# haltium_isimcore register map
Vendor: Nordic Semiconductor; Series: nRFHaltium; File version: 1
CPU: CM33 r0p4, little endian, MPU, FPU, 3 interrupt priority bits, 480 interrupts
Registers are 32-bit, read-write, reset 0x0 unless marked. A register's access mark holds for its fields unless they carry their own. Offsets are from the block's base; [hi:lo] are bit positions; {n}, {i} and the like mark numbered series.

## GLOBAL_TSGEN_NS — GENERIC
Base 0xBF041000
Same registers: GENERIC6_NS 0x47021000, GENERIC7_NS 0x47022000, GENERIC8_NS 0x47023000, GENERIC9_NS 0x47024000, GENERIC6_S 0x57021000, GENERIC7_S 0x57022000, GENERIC8_S 0x57023000, GENERIC9_S 0x57024000, GLOBAL_ETB_NS 0xBF044000, GLOBAL_ETR_NS 0xBF045000
0x00 TASKS_GENERICTASK wo — Generic event
  [0] TASKS_GENERICTASK
    1=Trigger task
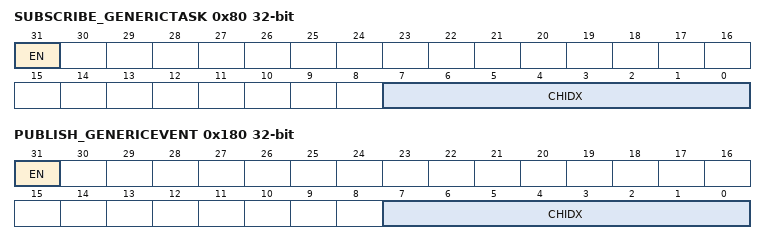
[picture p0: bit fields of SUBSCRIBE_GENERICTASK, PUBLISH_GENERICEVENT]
0x80 SUBSCRIBE_GENERICTASK — Subscribe configuration for task GENERICTASK
  [31] EN
    0=Disabled (Disable subscription); 1=Enabled (Enable subscription)
  [7:0] CHIDX — DPPI channel that task GENERICTASK will subscribe to
0x100 EVENTS_GENERICEVENT — Generic event
  [0] EVENTS_GENERICEVENT
    0=NotGenerated (Event not generated); 1=Generated (Event generated)
0x180 PUBLISH_GENERICEVENT — Publish configuration for event GENERICEVENT
  [31] EN
    0=Disabled (Disable publishing); 1=Enabled (Enable publishing)
  [7:0] CHIDX — DPPI channel that event GENERICEVENT will publish to
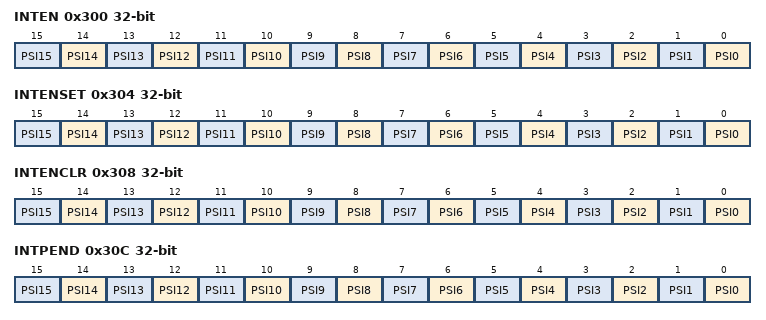
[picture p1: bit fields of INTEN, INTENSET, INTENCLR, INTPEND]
0x300 INTEN — Enable or disable interrupt
  [0] GENERICEVENT — Enable or disable interrupt for event GENERICEVENT
    0=Disabled; 1=Enabled
0x304 INTENSET — Enable interrupt
  [0] GENERICEVENT — Write '1' to enable interrupt for event GENERICEVENT
    on read: 0=Disabled (Read: Disabled); 1=Enabled (Read: Enabled) | on write: 1=Set (Enable)
0x308 INTENCLR — Disable interrupt
  [0] GENERICEVENT — Write '1' to disable interrupt for event GENERICEVENT
    on read: 0=Disabled (Read: Disabled); 1=Enabled (Read: Enabled) | on write: 1=Clear (Disable)

## CPUCONF_NS — CPU Configuration 0
Base 0x47001000
Same registers: CPUCONF_S 0x57001000
0x00 TASKS_ERASECACHE wo — Erase the caches used by the CPU.
  [0] TASKS_ERASECACHE
    1=Trigger task
0x500 INITSVTOR — Initial value of the secure VTOR (Vector Table Offset Register) after CPU reset.
  [31:0] INITSVTOR — Initial value of the VTOR.
0x504 INITNSVTOR — Initial value of the non-secure VTOR (Vector Table Offset Register).
  [31:0] INITNSVTOR — Initial value of the VTOR.
0x508 CPUSTART — Enable for starting the CPU
  [0] EN — Enable to start the CPU.
    0=Stopped (CPU stopped.); 1=Started (CPU started.)
0x50C CPUWAIT — Enable for the CPU wait.
  [0] EN — Enable to the CPU wait.
    0=Disabled (CPU is not waiting.); 1=Enabled (CPU is waiting.)

## CICTRL_NS — CI control 0
Base 0x47002000
Same registers: CICTRL_S 0x57002000
{0x100+4i} EVENTS_PSI[{i}] (i=0..15) — Description collection: Event generated from CryptoIsland Persistent State Interface PSI[n]
  [0] EVENTS_PSI — Event generated from CryptoIsland Persistent State Interface PSI[n]
    0=NotGenerated (Event not generated); 1=Generated (Event generated)
0x300 INTEN — Enable or disable interrupt
  [all] fields
    0=Disabled; 1=Enabled
  [n] PSI{n} (n=0..15) — Enable or disable interrupt for event PSI[{n}]
0x304 INTENSET — Enable interrupt
  [all] fields
    on read: 0=Disabled (Read: Disabled); 1=Enabled (Read: Enabled) | on write: 1=Set (Enable)
  [n] PSI{n} (n=0..15) — Write '1' to enable interrupt for event PSI[{n}]
0x308 INTENCLR — Disable interrupt
  [all] fields
    on read: 0=Disabled (Read: Disabled); 1=Enabled (Read: Enabled) | on write: 1=Clear (Disable)
  [n] PSI{n} (n=0..15) — Write '1' to disable interrupt for event PSI[{n}]
0x30C INTPEND ro — Pending interrupts
  [all] fields
    on read: 0=NotPending (Read: Not pending); 1=Pending (Read: Pending)
  [n] PSI{n} (n=0..15) — Read pending status of interrupt for event PSI[{n}]
0x400 PSI ro — CryptoIsland PSI status shadow register
  [15:0] PSI
0x404 POWERMODE reset 0x3 — CryptoIsland power mode control
  [1:0] POWERMODE
    0=SHUTDOWN (CryptoIsland to be put to shutdown mode); 1=HIBERNATE (CryptoIsland to be put to hibernate mode); 2=RETENTION (Reserved for future use); 3=RUN (Reserved for future use)
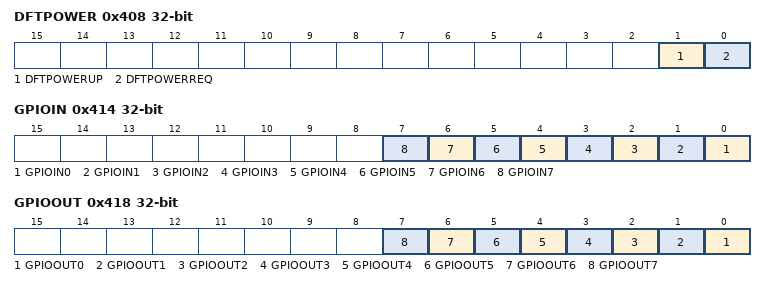
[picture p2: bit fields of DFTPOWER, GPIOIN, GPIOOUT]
0x408 DFTPOWER — CryptoIsland DFT power control
  [1] DFTPOWERUP — CryptoIsland DFT power up acknowledge
    0=OFF (Power up ack off); 1=ON (Power up ack on)
  [0] DFTPOWERREQ — CryptoIsland DFT power request
    0=OFF (Power request off); 1=ON (Power request on)
0x40C DFTRESET — CryptoIsland DFT reset control. DFTRESET applies to the needs of the iSIM core DFT mode and it can also be used as a normal mode reset to reset all non-hibernate logic of CryptoIsland. DFTRESET toggles SYSRSTn input of CryptoIsland.
  [0] DFTRESETREQ — CryptoIsland DFT reset request
    0=OFF (Reset request off); 1=ON (Reset request on)
0x410 FULLRESET — CryptoIsland full reset control. FULLRESET toggles SYSRSTn and HIB_SYSRSTn inputs of CryptoIsland and can be used to reset all logic of CryptoIsland.
  [0] FULLRESETREQ — CryptoIsland full reset request
    0=OFF (Reset request off); 1=ON (Reset request on)
0x414 GPIOIN — CryptoIsland GPIO input
  [all] fields
    0=Low (Drive GPIOIN low); 1=High (Drive GPIOIN high)
  [n] GPIOIN{n} (n=0..7) — CryptoIsland GPIOIN[{n}]
0x418 GPIOOUT ro — CryptoIsland GPIO output
  [all] fields
    0=Low (GPIOOUT is low); 1=High (GPIOOUT is high)
  [n] GPIOOUT{n} (n=0..7) — CryptoIsland GPIOOUT[{n}]

## Notices in the file
Copyright (c) 2010 - 2021, Nordic Semiconductor ASA
All rights reserved.
Redistribution and use in source and binary forms, with or without modification,
are permitted provided that the following conditions are met:
1. Redistributions of source code must retain the above copyright notice, this
list of conditions and the following disclaimer.
2. Redistributions in binary form, except as embedded into a Nordic
Semiconductor ASA integrated circuit in a product or a software update for
such product, must reproduce the above copyright notice, this list of
conditions and the following disclaimer in the documentation and/or other
materials provided with the distribution.
3. Neither the name of Nordic Semiconductor ASA nor the names of its
contributors may be used to endorse or promote products derived from this
software without specific prior written permission.
4. This software, with or without modification, must only be used with a
Nordic Semiconductor ASA integrated circuit.
5. Any software provided in binary form under this license must not be reverse
engineered, decompiled, modified and/or disassembled.
THIS SOFTWARE IS PROVIDED BY NORDIC SEMICONDUCTOR ASA "AS IS" AND ANY EXPRESS
OR IMPLIED WARRANTIES, INCLUDING, BUT NOT LIMITED TO, THE IMPLIED WARRANTIES
OF MERCHANTABILITY, NONINFRINGEMENT, AND FITNESS FOR A PARTICULAR PURPOSE ARE
DISCLAIMED. IN NO EVENT SHALL NORDIC SEMICONDUCTOR ASA OR CONTRIBUTORS BE
LIABLE FOR ANY DIRECT, INDIRECT, INCIDENTAL, SPECIAL, EXEMPLARY, OR
CONSEQUENTIAL DAMAGES (INCLUDING, BUT NOT LIMITED TO, PROCUREMENT OF SUBSTITUTE
GOODS OR SERVICES; LOSS OF USE, DATA, OR PROFITS; OR BUSINESS INTERRUPTION)
HOWEVER CAUSED AND ON ANY THEORY OF LIABILITY, WHETHER IN CONTRACT, STRICT
LIABILITY, OR TORT (INCLUDING NEGLIGENCE OR OTHERWISE) ARISING IN ANY WAY OUT
OF THE USE OF THIS SOFTWARE, EVEN IF ADVISED OF THE POSSIBILITY OF SUCH DAMAGE.
